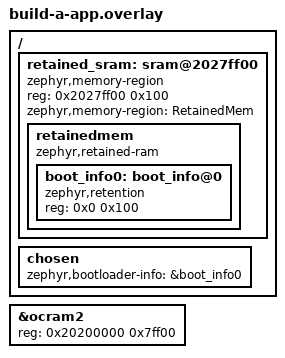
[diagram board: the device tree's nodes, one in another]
/* Trial overlay (issue #141, build A). Same node in MCUboot and application. */
/ {
	retained_sram: sram@2027ff00 {
		compatible = "zephyr,memory-region", "mmio-sram";
		reg = <0x2027ff00 0x100>;
		ranges = <0x0 0x2027ff00 0x100>;
		zephyr,memory-region = "RetainedMem";
		status = "okay";
		#address-cells = <1>;
		#size-cells = <1>;

		retainedmem {
			compatible = "zephyr,retained-ram";
			status = "okay";
			ranges;
			#address-cells = <1>;
			#size-cells = <1>;

			boot_info0: boot_info@0 {
				compatible = "zephyr,retention";
				status = "okay";
				reg = <0x0 0x100>;
			};
		};
	};

	chosen {
		zephyr,bootloader-info = &boot_info0;
	};
};

/* Retained region must not be part of any image's RAM: trim OCRAM2 by 256 B in both images. */
&ocram2 {
	reg = <0x20200000 0x7ff00>;
};
